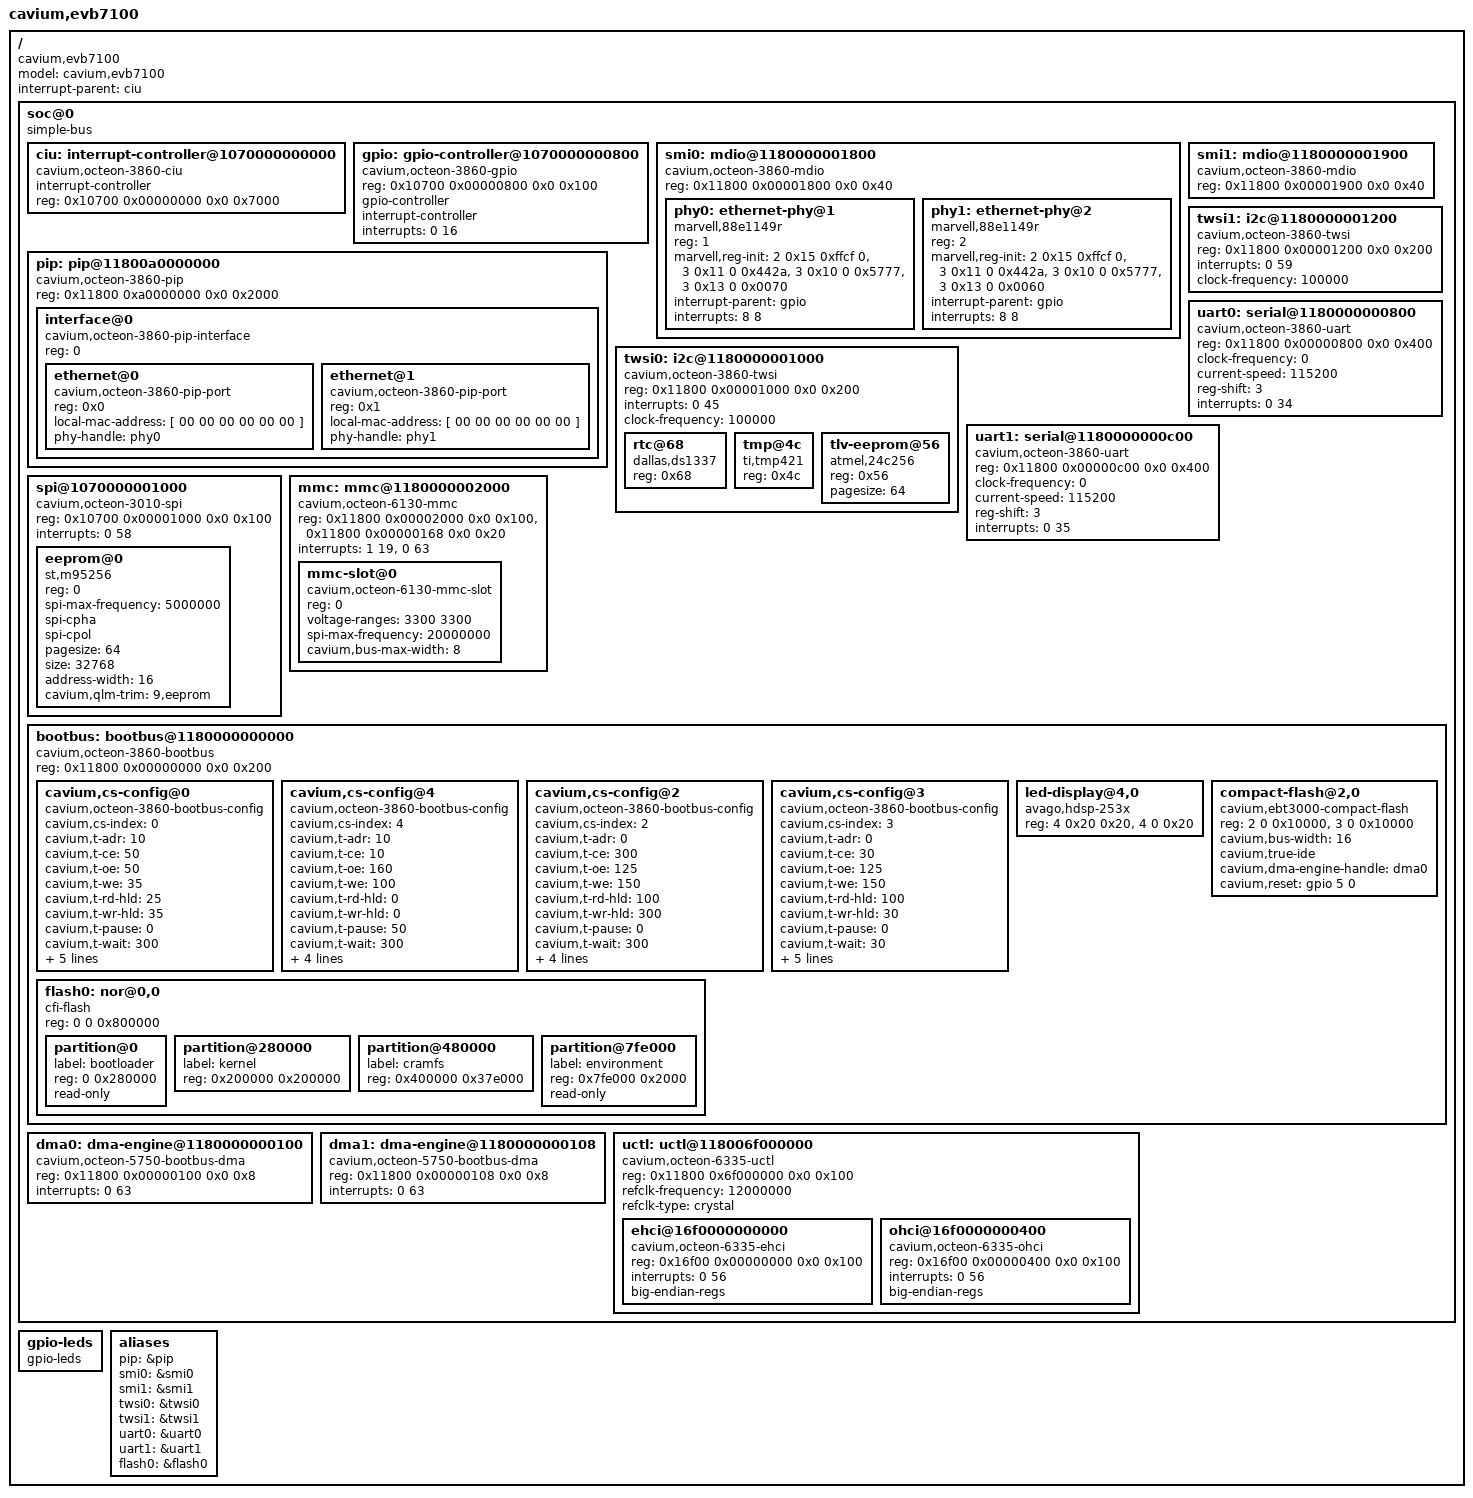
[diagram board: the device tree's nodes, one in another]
/dts-v1/;
/*
 * Cavium Inc. EVB7100 board
 */
/ {
	model = "cavium,evb7100";
	compatible = "cavium,evb7100";
	#address-cells = <2>;
	#size-cells = <2>;
	interrupt-parent = <&ciu>;

	soc@0 {
		compatible = "simple-bus";
		#address-cells = <2>;
		#size-cells = <2>;
		ranges; /* Direct mapping */

		ciu: interrupt-controller@1070000000000 {
			compatible = "cavium,octeon-3860-ciu";
			interrupt-controller;
			/* Interrupts are specified by two parts:
			 * 1) Controller register (0 or 1)
			 * 2) Bit within the register (0..63)
			 */
			#interrupt-cells = <2>;
			reg = <0x10700 0x00000000 0x0 0x7000>;
		};

		gpio: gpio-controller@1070000000800 {
			#gpio-cells = <2>;
			compatible = "cavium,octeon-3860-gpio";
			reg = <0x10700 0x00000800 0x0 0x100>;
			gpio-controller;
			/* Interrupts are specified by two parts:
			 * 1) GPIO pin number (0..15)
			 * 2) Triggering (1 - edge rising
			 *		  2 - edge falling
			 *		  4 - level active high
			 *		  8 - level active low)
			 */
			interrupt-controller;
			#interrupt-cells = <2>;
			/* The GPIO pins connect to 16 consecutive CUI bits */
			interrupts = <0 16>; /* <0 17> <0 18> <0 19>
				     <0 20> <0 21> <0 22> <0 23>
				     <0 24> <0 25> <0 26> <0 27>
				     <0 28> <0 29> <0 30> <0 31>; */
		};

		smi0: mdio@1180000001800 {
			compatible = "cavium,octeon-3860-mdio";
			#address-cells = <1>;
			#size-cells = <0>;
			reg = <0x11800 0x00001800 0x0 0x40>;

			phy0: ethernet-phy@1 {
				compatible = "marvell,88e1149r", "ethernet-phy-ieee802.3-c22";
				reg = <1>;
				marvell,reg-init =
					/* Fix rx and tx clock transition timing */
					<2 0x15 0xffcf 0>, /* Reg 2,21 Clear bits 4, 5 */
					/* Adjust LED drive. */
					<3 0x11 0 0x442a>, /* Reg 3,17 <- 0442a */
					/* irq, blink-activity, blink-link */
					<3 0x10 0 0x5777>, /* Reg 3,16 <- 0x5777 */
					<3 0x13 0 0x0070>; /* Reg 3,19 <- 0x0070 */
				interrupt-parent = <&gpio>;
				interrupts = <8 8>;	/* pin 8, active low */
			};

			phy1: ethernet-phy@2 {
				compatible = "marvell,88e1149r", "ethernet-phy-ieee802.3-c22";
				reg = <2>;
				marvell,reg-init =
					/* Fix rx and tx clock transition timing */
					<2 0x15 0xffcf 0>, /* Reg 2,21 Clear bits 4, 5 */
					/* Adjust LED drive. */
					<3 0x11 0 0x442a>, /* Reg 3,17 <- 0442a */
					/* irq, blink-activity, blink-link */
					/* irq, blink-activity, blink-link */
					<3 0x10 0 0x5777>, /* Reg 3,16 <- 0x5777 */
					<3 0x13 0 0x0060>; /* Reg 3,19 <- 0x0060 */
				interrupt-parent = <&gpio>;
				interrupts = <8 8>;	/* pin 8, active low */
			};

		};

		smi1: mdio@1180000001900 {
			compatible = "cavium,octeon-3860-mdio";
			#address-cells = <1>;
			#size-cells = <0>;
			reg = <0x11800 0x00001900 0x0 0x40>;
		};

		pip: pip@11800a0000000 {
			compatible = "cavium,octeon-3860-pip";
			#address-cells = <1>;
			#size-cells = <0>;
			reg = <0x11800 0xa0000000 0x0 0x2000>;

			interface@0 {
				compatible = "cavium,octeon-3860-pip-interface";
				#address-cells = <1>;
				#size-cells = <0>;
				reg = <0>; /* interface */

				ethernet@0 {
					compatible = "cavium,octeon-3860-pip-port";
					reg = <0x0>; /* Port */
					local-mac-address = [ 00 00 00 00 00 00 ];
					phy-handle = <&phy0>;
				};
				ethernet@1 {
					compatible = "cavium,octeon-3860-pip-port";
					reg = <0x1>; /* Port */
					local-mac-address = [ 00 00 00 00 00 00 ];
					phy-handle = <&phy1>;
				};
			};


                };

		twsi0: i2c@1180000001000 {
			#address-cells = <1>;
			#size-cells = <0>;
			compatible = "cavium,octeon-3860-twsi";
			reg = <0x11800 0x00001000 0x0 0x200>;
			interrupts = <0 45>;
			clock-frequency = <100000>;

			rtc@68 {
				compatible = "dallas,ds1337";
				reg = <0x68>;
			};
			tmp@4c {
				compatible = "ti,tmp421";
				reg = <0x4c>;
			};
			tlv-eeprom@56 {
				compatible = "atmel,24c256";
				reg = <0x56>;
				pagesize = <64>;
			};
		};

		twsi1: i2c@1180000001200 {
			#address-cells = <1>;
			#size-cells = <0>;
			compatible = "cavium,octeon-3860-twsi";
			reg = <0x11800 0x00001200 0x0 0x200>;
			interrupts = <0 59>;
			clock-frequency = <100000>;
		};

		uart0: serial@1180000000800 {
			compatible = "cavium,octeon-3860-uart","ns16550";
			reg = <0x11800 0x00000800 0x0 0x400>;
			clock-frequency = <0>;
			current-speed = <115200>;
			reg-shift = <3>;
			interrupts = <0 34>;
		};

		uart1: serial@1180000000c00 {
			compatible = "cavium,octeon-3860-uart","ns16550";
			reg = <0x11800 0x00000c00 0x0 0x400>;
			clock-frequency = <0>;
			current-speed = <115200>;
			reg-shift = <3>;
			interrupts = <0 35>;
		};

		spi@1070000001000 {
			compatible = "cavium,octeon-3010-spi";
			reg = <0x10700 0x00001000 0x0 0x100>;
			interrupts = <0 58>;
			#address-cells = <1>;
			#size-cells = <0>;

			eeprom@0 {
				compatible = "st,m95256", "atmel,at25";
				reg = <0>;
				spi-max-frequency = <5000000>;
				spi-cpha;
				spi-cpol;

				pagesize = <64>;
				size = <32768>;
				address-width = <16>;
				cavium,qlm-trim = "9,eeprom";
			};
		};

		mmc: mmc@1180000002000 {
			compatible = "cavium,octeon-6130-mmc";
			reg = <0x11800 0x00002000 0x0 0x100>,
			      <0x11800 0x00000168 0x0 0x20>;
			#address-cells = <1>;
			#size-cells = <0>;
			/* EMM irq, DMA irq */
			interrupts = <1 19>, <0 63>;

			/* The board only has a single MMC slot */
			mmc-slot@0 {
				compatible = "cavium,octeon-6130-mmc-slot",
					     "mmc-spi-slot";
				reg = <0>;
				voltage-ranges = <3300 3300>;
				spi-max-frequency = <20000000>;
				/* bus width can be 1, 4 or 8 */
				cavium,bus-max-width = <8>;
			};
		};

		bootbus: bootbus@1180000000000 {
			compatible = "cavium,octeon-3860-bootbus";
			reg = <0x11800 0x00000000 0x0 0x200>;
			/* The chip select number and offset */
			#address-cells = <2>;
			/* The size of the chip select region */
			#size-cells = <1>;
			ranges = <0 0  0       0x1f400000  0xc00000>,
				 <1 0  0x10000 0x30000000  0>,
				 <2 0  0       0x1d040000  0x10000>,
				 <3 0  0       0x1d050000  0x10000>,
				 <4 0  0       0x1d020000  0x10000>,
				 <5 0  0x10000 0x40000000  0>,
				 <6 0  0x10000 0x50000000  0>,
				 <7 0  0x10000 0x90000000  0>;

			cavium,cs-config@0 {
				compatible = "cavium,octeon-3860-bootbus-config";
				cavium,cs-index = <0>;
				cavium,t-adr  = <10>;
				cavium,t-ce   = <50>;
				cavium,t-oe   = <50>;
				cavium,t-we   = <35>;
				cavium,t-rd-hld = <25>;
				cavium,t-wr-hld = <35>;
				cavium,t-pause  = <0>;
				cavium,t-wait   = <300>;
				cavium,t-page   = <25>;
				cavium,t-rd-dly = <0>;

				cavium,page-mode = <1>;
				cavium,pages     = <8>;
				cavium,bus-width = <8>;
			};
			cavium,cs-config@4 {
				compatible = "cavium,octeon-3860-bootbus-config";
				cavium,cs-index = <4>;
				cavium,t-adr  = <10>;
				cavium,t-ce   = <10>;
				cavium,t-oe   = <160>;
				cavium,t-we   = <100>;
				cavium,t-rd-hld = <0>;
				cavium,t-wr-hld = <0>;
				cavium,t-pause  = <50>;
				cavium,t-wait   = <300>;
				cavium,t-page   = <300>;
				cavium,t-rd-dly = <10>;

				cavium,pages     = <0>;
				cavium,bus-width = <8>;
			};
			cavium,cs-config@2 {
				compatible = "cavium,octeon-3860-bootbus-config";
				cavium,cs-index = <2>;
				cavium,t-adr  = <0>;
				cavium,t-ce   = <300>;
				cavium,t-oe   = <125>;
				cavium,t-we   = <150>;
				cavium,t-rd-hld = <100>;
				cavium,t-wr-hld = <300>;
				cavium,t-pause  = <0>;
				cavium,t-wait   = <300>;
				cavium,t-page   = <300>;
				cavium,t-rd-dly = <0>;

				cavium,pages     = <0>;
				cavium,bus-width = <16>;
			};
			cavium,cs-config@3 {
				compatible = "cavium,octeon-3860-bootbus-config";
				cavium,cs-index = <3>;
				cavium,t-adr  = <0>;
				cavium,t-ce   = <30>;
				cavium,t-oe   = <125>;
				cavium,t-we   = <150>;
				cavium,t-rd-hld = <100>;
				cavium,t-wr-hld = <30>;
				cavium,t-pause  = <0>;
				cavium,t-wait   = <30>;
				cavium,t-page   = <300>;
				cavium,t-rd-dly = <0>;

				cavium,pages     = <0>;
				cavium,wait-mode;
				cavium,bus-width = <16>;
			};

			flash0: nor@0,0 {
				compatible = "cfi-flash";
				reg = <0 0 0x800000>;
				#address-cells = <1>;
				#size-cells = <1>;

				partition@0 {
					label = "bootloader";
					reg = <0 0x280000>;
					read-only;
				};
				partition@280000 {
					label = "kernel";
					reg = <0x200000 0x200000>;
				};
				partition@480000 {
					label = "cramfs";
					reg = <0x400000 0x37e000>;
				};
				partition@7fe000 {
					label = "environment";
					reg = <0x7fe000 0x2000>;
					read-only;
				};
			};

			led-display@4,0 {
				compatible = "avago,hdsp-253x";
				reg = <4 0x20 0x20>, <4 0 0x20>;
			};

			compact-flash@2,0 {
				compatible = "cavium,ebt3000-compact-flash";
				reg = <2 0 0x10000>, <3 0 0x10000>;
				cavium,bus-width = <16>;
				cavium,true-ide;
				cavium,dma-engine-handle = <&dma0>;
				cavium,reset = <&gpio 5 0>;
			};
		};

		dma0: dma-engine@1180000000100 {
			compatible = "cavium,octeon-5750-bootbus-dma";
			reg = <0x11800 0x00000100 0x0 0x8>;
			interrupts = <0 63>;
		};
		dma1: dma-engine@1180000000108 {
			compatible = "cavium,octeon-5750-bootbus-dma";
			reg = <0x11800 0x00000108 0x0 0x8>;
			interrupts = <0 63>;
		};

		uctl: uctl@118006f000000 {
			compatible = "cavium,octeon-6335-uctl";
			reg = <0x11800 0x6f000000 0x0 0x100>;
			ranges; /* Direct mapping */
			#address-cells = <2>;
			#size-cells = <2>;
			/* 12MHz, 24MHz and 48MHz allowed */
			refclk-frequency = <12000000>;
			/* Either "crystal" or "external" */
			refclk-type = "crystal";

			ehci@16f0000000000 {
				compatible = "cavium,octeon-6335-ehci","usb-ehci";
				reg = <0x16f00 0x00000000 0x0 0x100>;
				interrupts = <0 56>;
				big-endian-regs;
			};
			ohci@16f0000000400 {
				compatible = "cavium,octeon-6335-ohci","usb-ohci";
				reg = <0x16f00 0x00000400 0x0 0x100>;
				interrupts = <0 56>;
				big-endian-regs;
			};
		};
	};


	gpio-leds {
		compatible = "gpio-leds";
	};

	aliases {
		pip = &pip;
		smi0 = &smi0;
		smi1 = &smi1;
		twsi0 = &twsi0;
		twsi1 = &twsi1;
		uart0 = &uart0;
		uart1 = &uart1;
		flash0 = &flash0;
	};
 };
